AUTOSAR XML (schema 00051)
# SPDX-License-Identifier: Apache-2.0
standard types defined: sint32, uint8
package /Components
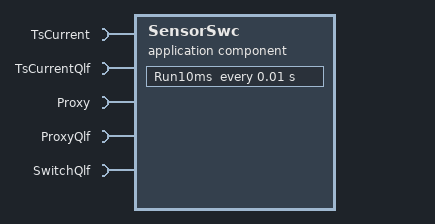
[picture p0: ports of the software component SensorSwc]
  application sw component type SensorSwc
    5 x require port:
      TsCurrent: nonqueued-receiver-com-spec{data-element=TsCurrent, init-value=-7}, required-interface=TsCurrent
      TsCurrentQlf: nonqueued-receiver-com-spec{data-element=TsCurrentQlf, init-value=0}, required-interface=TsCurrentQlf
      Proxy: nonqueued-receiver-com-spec{data-element=Proxy, init-value=0}, required-interface=Proxy
      ProxyQlf: nonqueued-receiver-com-spec{data-element=ProxyQlf, init-value=0}, required-interface=ProxyQlf
      SwitchQlf: nonqueued-receiver-com-spec{data-element=SwitchQlf, init-value=0}, required-interface=SwitchQlf
    behavior SensorSwc_IB
      timing event Event_Run10ms: start-on-event=Run10ms, period=0.01
      runnable Run10ms: symbol=SensorSwc_Run10ms
package /Interfaces
  5 x sender receiver interface:
    TsCurrent
      data TsCurrent: type=sint32
    TsCurrentQlf
      data TsCurrentQlf: type=uint8
    Proxy
      data Proxy: type=sint32
    ProxyQlf
      data ProxyQlf: type=uint8
    SwitchQlf
      data SwitchQlf: type=uint8
